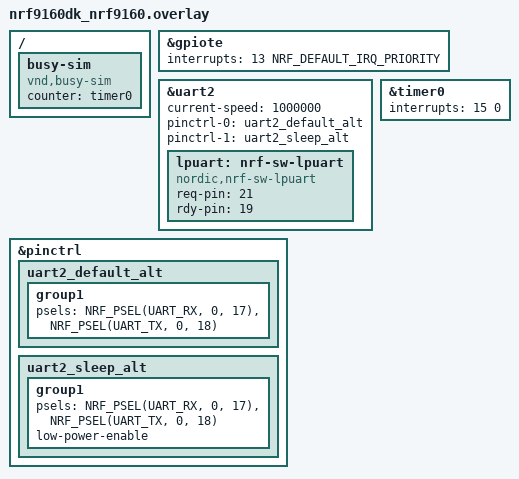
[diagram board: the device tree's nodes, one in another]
/*
 * Copyright (c) 2022 Nordic Semiconductor ASA
 *
 * SPDX-License-Identifier: LicenseRef-Nordic-5-Clause
 */
#include <nrf9160/nrf9160dk_nrf52840_reset_on_if5.dtsi>

&gpiote {
	interrupts = <13 NRF_DEFAULT_IRQ_PRIORITY>;
};

&uart2 {
	current-speed = <1000000>;
	status = "okay";
	pinctrl-0 = <&uart2_default_alt>; /* <&interface_to_nrf52840 1 0> */
	pinctrl-1 = <&uart2_sleep_alt>; /* <&interface_to_nrf52840 0 0> */
	/delete-property/ rts-pin;
	/delete-property/ cts-pin;
	/delete-property/ hw-flow-control;

	lpuart: nrf-sw-lpuart {
		compatible = "nordic,nrf-sw-lpuart";
		status = "okay";
		req-pin = <21>; /* <&interface_to_nrf52840 3 0>; */
		rdy-pin = <19>; /* <&interface_to_nrf52840 2 0>; */
	};
};

&pinctrl {
	uart2_default_alt: uart2_default_alt {
		group1 {
			psels = <NRF_PSEL(UART_RX, 0, 17)>,
				<NRF_PSEL(UART_TX, 0, 18)>;
		};
	};

	uart2_sleep_alt: uart2_sleep_alt {
		group1 {
			psels = <NRF_PSEL(UART_RX, 0, 17)>,
				<NRF_PSEL(UART_TX, 0, 18)>;
			low-power-enable;
		};
	};
};

&timer0 {
	status = "okay";
	interrupts = <15 0>;
};

/ {
	busy-sim {
		compatible = "vnd,busy-sim";
		status = "okay";
		counter = <&timer0>;
	};
};
